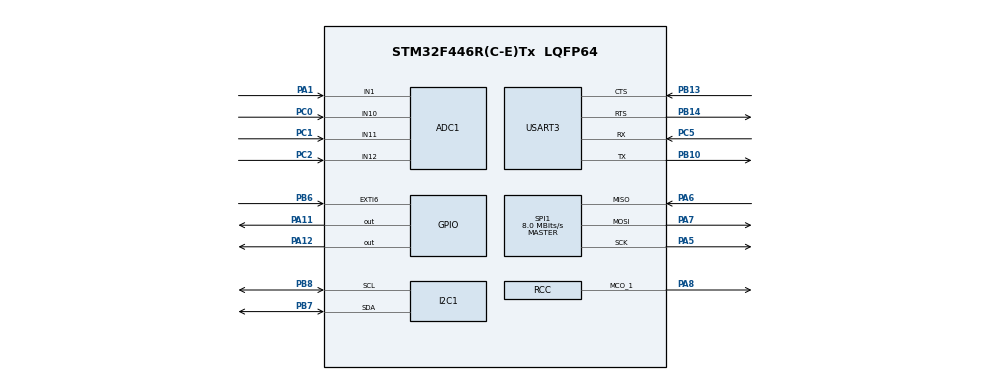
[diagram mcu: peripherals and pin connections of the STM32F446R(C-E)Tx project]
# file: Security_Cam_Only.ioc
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ADC1.Channel-1\#ChannelRegularConversion=ADC_CHANNEL_1
ADC1.NbrOfConversionFlag=1
ADC1.Rank-1\#ChannelRegularConversion=1
ADC1.SamplingTime-1\#ChannelRegularConversion=ADC_SAMPLETIME_3CYCLES
ADC1.master=1
Dma.Request0=USART3_RX
Dma.Request1=USART3_TX
Dma.USART3_RX.0.Direction=DMA_PERIPH_TO_MEMORY
Dma.USART3_RX.0.FIFOMode=DMA_FIFOMODE_ENABLE
Dma.USART3_RX.0.FIFOThreshold=DMA_FIFO_THRESHOLD_FULL
Dma.USART3_RX.0.Instance=DMA1_Stream1
Dma.USART3_RX.0.MemBurst=DMA_MBURST_SINGLE
Dma.USART3_RX.0.MemDataAlignment=DMA_MDATAALIGN_BYTE
Dma.USART3_RX.0.MemInc=DMA_MINC_ENABLE
Dma.USART3_RX.0.Mode=DMA_NORMAL
Dma.USART3_RX.0.PeriphBurst=DMA_PBURST_SINGLE
Dma.USART3_RX.0.PeriphDataAlignment=DMA_PDATAALIGN_BYTE
Dma.USART3_RX.0.PeriphInc=DMA_PINC_DISABLE
Dma.USART3_RX.0.Priority=DMA_PRIORITY_LOW
Dma.USART3_TX.1.Direction=DMA_MEMORY_TO_PERIPH
Dma.USART3_TX.1.FIFOMode=DMA_FIFOMODE_ENABLE
Dma.USART3_TX.1.FIFOThreshold=DMA_FIFO_THRESHOLD_FULL
Dma.USART3_TX.1.Instance=DMA1_Stream3
Dma.USART3_TX.1.MemBurst=DMA_MBURST_SINGLE
Dma.USART3_TX.1.MemDataAlignment=DMA_MDATAALIGN_BYTE
Dma.USART3_TX.1.MemInc=DMA_MINC_ENABLE
Dma.USART3_TX.1.Mode=DMA_NORMAL
Dma.USART3_TX.1.PeriphBurst=DMA_PBURST_SINGLE
Dma.USART3_TX.1.PeriphDataAlignment=DMA_PDATAALIGN_BYTE
Dma.USART3_TX.1.PeriphInc=DMA_PINC_DISABLE
Dma.USART3_TX.1.Priority=DMA_PRIORITY_LOW
I2C1.I2C_Mode=I2C_Standard
Mcu.Family=STM32F4
Mcu.Name=STM32F446R(C-E)Tx
Mcu.Package=LQFP64
NVIC.DMA1_Stream1_IRQn=true\:0\:0\:false\:false\:true\:false\:true\:true
NVIC.DMA1_Stream3_IRQn=true\:0\:0\:false\:false\:true\:false\:true\:true
NVIC.EXTI9_5_IRQn=true\:0\:0\:false\:false\:true\:true\:true\:true
NVIC.I2C1_EV_IRQn=true\:0\:0\:false\:false\:true\:true\:true\:true
NVIC.PriorityGroup=NVIC_PRIORITYGROUP_4
NVIC.RTC_WKUP_IRQn=true\:0\:0\:false\:false\:true\:true\:true\:true
NVIC.SPI1_IRQn=true\:0\:0\:false\:false\:true\:true\:true\:true
NVIC.TIM1_BRK_TIM9_IRQn=true\:0\:0\:false\:false\:true\:true\:true\:true
NVIC.USART3_IRQn=true\:0\:0\:false\:false\:true\:true\:true\:true
PA1.Signal=ADCx_IN1
PA11.Signal=GPIO_Output
PA12.Signal=GPIO_Output
PA13.Mode=Serial_Wire
PA13.Signal=SYS_JTMS-SWDIO
PA14.Mode=Serial_Wire
PA14.Signal=SYS_JTCK-SWCLK
PA5.Mode=Full_Duplex_Master
PA5.Signal=SPI1_SCK
PA6.Mode=Full_Duplex_Master
PA6.Signal=SPI1_MISO
PA7.Mode=Full_Duplex_Master
PA7.Signal=SPI1_MOSI
PA8.Mode=Clock-out-1
PA8.Signal=RCC_MCO_1
PB10.Mode=Asynchronous
PB10.Signal=USART3_TX
PB13.Mode=CTS_RTS
PB13.Signal=USART3_CTS
PB14.Mode=CTS_RTS
PB14.Signal=USART3_RTS
PB6.Signal=GPXTI6
PB7.Mode=I2C
PB7.Signal=I2C1_SDA
PB8.Mode=I2C
PB8.Signal=I2C1_SCL
PC0.Signal=ADCx_IN10
PC1.Signal=ADCx_IN11
PC14-OSC32_IN.Mode=LSE-External-Oscillator
PC14-OSC32_IN.Signal=RCC_OSC32_IN
PC15-OSC32_OUT.Mode=LSE-External-Oscillator
PC15-OSC32_OUT.Signal=RCC_OSC32_OUT
PC2.Signal=ADCx_IN12
PC5.Mode=Asynchronous
PC5.Signal=USART3_RX
PH0-OSC_IN.Mode=HSE-External-Clock-Source
PH0-OSC_IN.Signal=RCC_OSC_IN
PH1-OSC_OUT.Mode=HSE-External-Clock-Source
PH1-OSC_OUT.Signal=RCC_OSC_OUT
ProjectManager.HeapSize=0x200
ProjectManager.StackSize=0x400
ProjectManager.TargetToolchain=STM32CubeIDE
RCC.CortexFreq_Value=16000000
RCC.USBFreq_Value=96000000
RCC.VCOOutputFreq_Value=192000000
SH.ADCx_IN1.0=ADC1_IN1,IN1
SH.ADCx_IN10.0=ADC1_IN10,IN10
SH.ADCx_IN11.0=ADC1_IN11,IN11
SH.ADCx_IN12.0=ADC1_IN12,IN12
SPI1.CalculateBaudRate=8.0 MBits/s
SPI1.Direction=SPI_DIRECTION_2LINES
SPI1.Mode=SPI_MODE_MASTER
SPI1.VirtualType=VM_MASTER
USART3.VirtualMode=VM_ASYNC
VP_RTC_VS_RTC_Activate.Mode=RTC_Enabled
VP_RTC_VS_RTC_WakeUp_intern.Mode=WakeUp
VP_TIM1_VS_ClockSourceITR.Mode=TriggerSource_ITR0
board=custom

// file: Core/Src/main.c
/* USER CODE BEGIN Header */
/**
  ******************************************************************************
  * @file           : main.c
  * @brief          : Main program body
  ******************************************************************************
  * @attention
  *
  * Copyright (c) 2026 STMicroelectronics.
  * All rights reserved.
  *
  * This software is licensed under terms that can be found in the LICENSE file
  * in the root directory of this software component.
  * If no LICENSE file comes with this software, it is provided AS-IS.
  *
  ******************************************************************************
  */
/* USER CODE END Header */
#include "main.h"

/* USER CODE BEGIN Includes */
#include "accelerometer.h"
#include "status.h"
#include "stm_hal.h"
#include "stm32f4xx_it.h"
#include <stdbool.h>
/* USER CODE END Includes */

/* USER CODE BEGIN PTD */
extern volatile bool accelDataReady;
/* USER CODE END PTD */

//ADC_HandleTypeDef hadc1;
//
//I2C_HandleTypeDef hi2c1;
//
//RTC_HandleTypeDef hrtc;
//
//SPI_HandleTypeDef hspi1;
//
//TIM_HandleTypeDef htim1;
//
//UART_HandleTypeDef huart3;
//DMA_HandleTypeDef hdma_usart3_rx;
//DMA_HandleTypeDef hdma_usart3_tx;

//void SystemClock_Config(void);
//static void MX_GPIO_Init(void);
//static void MX_DMA_Init(void);
//static void MX_I2C1_Init(void);
//static void MX_RTC_Init(void);
//static void MX_TIM1_Init(void);
//static void MX_ADC1_Init(void);
//static void MX_SPI1_Init(void);
//static void MX_USART3_UART_Init(void);

int main(void)
{

  /* MCU Configuration--------------------------------------------------------*/

  /* Reset of all peripherals, Initializes the Flash interface and the Systick. */
  HAL_Init();

  /* Configure the system clock */
  SystemClock_Config();

  /* Initialize all configured peripherals */
  MX_GPIO_Init();
  MX_DMA_Init();
  MX_I2C1_Init();
  MX_RTC_Init();
  MX_TIM1_Init();
  MX_ADC1_Init();
  MX_SPI1_Init();
  MX_USART3_UART_Init();
  /* USER CODE BEGIN 2 */

  //initialize
  statusDefinition_enum accelStatus = accelerometerInitialization();

  /* USER CODE END 2 */

  /* Infinite loop */
  while (1)
  {

    /* USER CODE BEGIN 3 */
	  if (accelDataReady)
	  {
		  accelData_s currentAccelData = getAccelerometerData();
		  accelDataReady = false;
		  float x = currentAccelData.x_data;
	  }
  }
  /* USER CODE END 3 */
}

//void Error_Handler(void)
//{
//  /* USER CODE BEGIN Error_Handler_Debug */
//  /* User can add his own implementation to report the HAL error return state */
//  __disable_irq();
//  while (1)
//  {
//  }
//  /* USER CODE END Error_Handler_Debug */
//}
